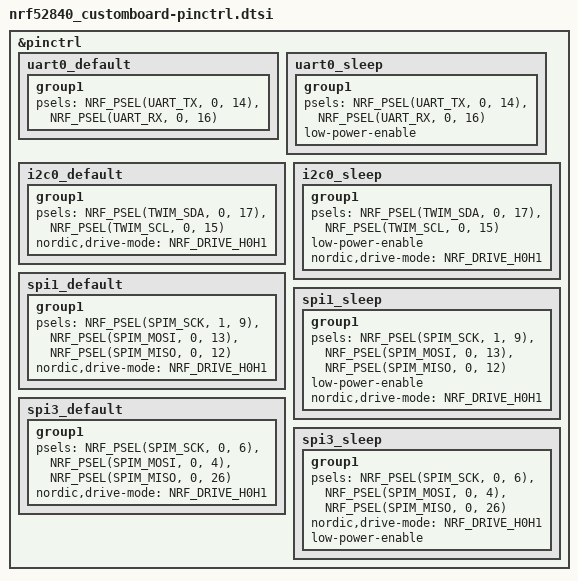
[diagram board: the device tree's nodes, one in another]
/*
 * SPDX-License-Identifier: Apache-2.0
 */

&pinctrl {
	uart0_default: uart0_default {
		group1 {
			psels = <NRF_PSEL(UART_TX, 0, 14)>,
				<NRF_PSEL(UART_RX, 0, 16)>;
		};
	};

	uart0_sleep: uart0_sleep {
		group1 {
			psels = <NRF_PSEL(UART_TX, 0, 14)>,
				<NRF_PSEL(UART_RX, 0, 16)>;
			low-power-enable;
		};
	};

	i2c0_default: i2c0_default {
		group1 {
			psels = <NRF_PSEL(TWIM_SDA, 0, 17)>,
				<NRF_PSEL(TWIM_SCL, 0, 15)>;
			nordic,drive-mode = <NRF_DRIVE_H0H1>;
		};
	};

	i2c0_sleep: i2c0_sleep {
		group1 {
			psels = <NRF_PSEL(TWIM_SDA, 0, 17)>,
				<NRF_PSEL(TWIM_SCL, 0, 15)>;
			low-power-enable;
			nordic,drive-mode = <NRF_DRIVE_H0H1>;
		};
	};

	spi1_default: spi1_default {
		group1 {
			psels = <NRF_PSEL(SPIM_SCK, 1, 9)>,
				<NRF_PSEL(SPIM_MOSI, 0, 13)>,
				<NRF_PSEL(SPIM_MISO, 0, 12)>;
			nordic,drive-mode = <NRF_DRIVE_H0H1>;
		};
	};

	spi1_sleep: spi1_sleep {
		group1 {
			psels = <NRF_PSEL(SPIM_SCK, 1, 9)>,
				<NRF_PSEL(SPIM_MOSI, 0, 13)>,
				<NRF_PSEL(SPIM_MISO, 0, 12)>;
			low-power-enable;
			nordic,drive-mode = <NRF_DRIVE_H0H1>;
		};
	};

	spi3_default: spi3_default {
		group1 {
			psels = <NRF_PSEL(SPIM_SCK, 0, 6)>,
				<NRF_PSEL(SPIM_MOSI, 0, 4)>,
				<NRF_PSEL(SPIM_MISO, 0, 26)>;
			nordic,drive-mode = <NRF_DRIVE_H0H1>;
		};
	};

	spi3_sleep: spi3_sleep {
		group1 {
			psels = <NRF_PSEL(SPIM_SCK, 0, 6)>,
				<NRF_PSEL(SPIM_MOSI, 0, 4)>,
				<NRF_PSEL(SPIM_MISO, 0, 26)>;
			nordic,drive-mode = <NRF_DRIVE_H0H1>;
			low-power-enable;
		};
	};
};
